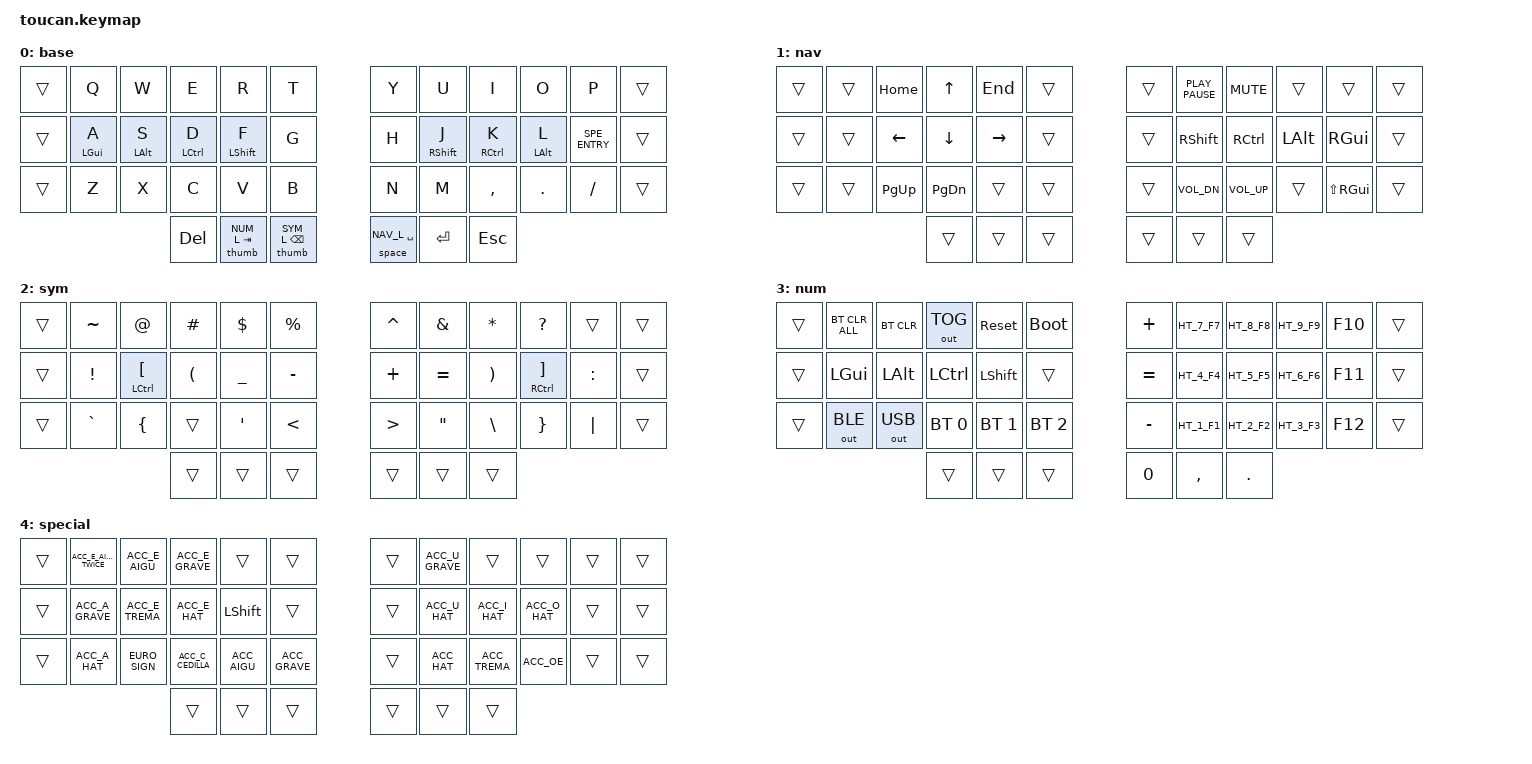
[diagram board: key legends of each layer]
/*
 * Copyright (c) 2021-2022 The ZMK Contributors
 *
 * SPDX-License-Identifier: MIT
 */

#include <behaviors.dtsi>
#include <input/processors.dtsi>
#include <dt-bindings/zmk/input_transform.h>
#include <dt-bindings/zmk/bt.h>
#include <dt-bindings/zmk/keys.h>
#include <dt-bindings/zmk/outputs.h>

#define BASE_L 0
#define NAV_L 1
#define SYM_L 2
#define NUM_L 3
#define SPE_L 4

// Keyboard keys positions
// 0  1  2  3  4  5               6  7  8  9  10 11
// 12 13 14 15 16 17             18 19 20 21 22 23
// 24 25 26 27 28 29             30 31 32 33 34 35
//             36 37 38        39 40 41
#define LEFT_HAND_KEYS                                      \
1  2  3  4  5                                               \
13 14 15 16 17                                              \
25 26 27 28 29

#define RIGHT_HAND_KEYS                                     \
                                    6  7  8  9  10          \
                                    18 19 20 21 22          \
                                    30 31 32 33 34

#define THUMB_KEYS                                          \
            36 37 38                39 40 41

&glidepoint_listener {
        input-processors = <&zip_xy_scaler 250 100>;
        precision_layer {
                layers = <2>;
                input-processors = <&zip_xy_scaler 110 100>;
        };
        scroller {
                layers = <3>;
                input-processors = <
                        &zip_xy_to_scroll_mapper
                        &zip_scroll_scaler 1 5
                        &zip_scroll_transform INPUT_TRANSFORM_X_INVERT
                >;
        };
};

/ {
        macros {
                #include "macros.dtsi"
        };

        combos {
                // Keyboard keys positions
                // 0  1  2  3  4  5               6  7  8  9  10 11
                // 12 13 14 15 16 17             18 19 20 21 22 23
                // 24 25 26 27 28 29             30 31 32 33 34 35
                //             36 37 38        39 40 41
                #define COMBO_KEYS_ESC 2 3 4 // "wer"

                #define COMBO_KEYS_SYM_CARET 1 13 // "qa"
                #define COMBO_KEYS_SYM_DOLLAR 5 17 // "tg"
                #define COMBO_KEYS_SYM_ASTERISK 6 18 // "yh"
                #define COMBO_KEYS_SYM_PLUS 26 14 // "xs"
                #define COMBO_KEYS_SYM_MINUS 33 21 // ".l"
                #define COMBO_KEYS_SYM_HASH 17 29 // "gb"
                #define COMBO_KEYS_SYM_GRAVE 13 25 // "az"

                #define COMBO_KEYS_ENTER 15 16 // "df"
                #define COMBO_KEYS_ENTER_CTRL 14 15 16 // "sdf"
                #define COMBO_KEYS_TAB 14 15 // "sd"

                #define COMBO_KEYS_CAPS 16 19 // "fj"
                #define COMBO_KEYS_APPS 25 34 // "z + /"

                #define COMBO_KEYS_VIM_SAVE 22 2 // "spe + w"
                #define COMBO_KEYS_VIM_SAVE_QUIT 22 1 // "spe + q"

                #define COMBO_KEYS_SYM_QUOTE 28 16 // "vf"
                #define COMBO_KEYS_SYM_DQUOTE 31 19 // "mj"
                #define COMBO_KEYS_SYM_LPAR 3 15 // "ed"
                #define COMBO_KEYS_SYM_RPAR 8 20 // "ik"
                #define COMBO_KEYS_SYM_LBKT 2 14 // "ws"
                #define COMBO_KEYS_SYM_RBKT 9 21 // "ol"
                #define COMBO_KEYS_SYM_EXCLAM 27 15 // "cd"
                #define COMBO_KEYS_SYM_QUESTION 32 20 // ",k"
                #define COMBO_KEYS_SYM_UNDER 4 16 // "rf"
                #define COMBO_KEYS_SYM_EQUAL 19 7 // "ju"
                #define COMBO_KEYS_SYM_AT 18 30 // "hn"
                #define COMBO_KEYS_SYM_COLON 10 22 // "p + spe"
                #define COMBO_KEYS_SYM_SEMI 22 34 // "spe/"

                #define COMBO_KEYS_CUT 25 26 // "zx"
                #define COMBO_KEYS_COPY 26 27 // "xc"
                #define COMBO_KEYS_PASTE 27 28 // "cv"
                #define COMBO_KEYS_SPACE 26 27 28 // "xcv"
                #define COMBO_KEYS_PLAIN_PASTE 28 29 // "vb"
                #include "combos.dtsi"
        };

        behaviors {
                #include "behaviors.dtsi"
                #include "home_rows.dtsi"
        };

        keymap {
                compatible = "zmk,keymap";

                base_layer {
                        display-name = "base";
                        bindings = <
&trans        &kp Q         &kp W         &kp E          &kp R           &kp T                       &kp Y  &kp U           &kp I          &kp O         &kp P         &trans
&trans        &hmrl LGUI A  &hmrl LALT S  &hmrl LCTRL D  &hmsl LSHIFT F  &kp G                       &kp H  &hmsr RSHIFT J  &hmrr RCTRL K  &hmrr LALT L  SPE_ENTRY    &trans
&trans        &kp Z         &kp X         &kp C          &kp V           &kp B                       &kp N  &kp M           &kp COMMA      &kp DOT       &kp SLASH     &trans
                                                            &kp DELETE  &thumb NUM_L TAB     &thumb SYM_L BACKSPACE    &space NAV_L SPACE  &kp ENTER  &kp ESC
                        >;
                };

                nav_layer {
                        display-name = "nav";
                        bindings = <
&trans  &trans          &kp HOME        &kp UP          &kp END           &trans                 &trans  &kp K_PLAY_PAUSE   &kp K_MUTE      &trans        &trans        &trans
&trans  &trans          &kp LEFT        &kp DOWN        &kp RIGHT         &trans                 &trans  &kp RSHIFT         &kp RCTRL       &kp LALT      &kp RGUI      &trans
&trans  &trans          &kp PAGE_UP     &kp PAGE_DOWN   &trans            &trans                 &trans  &kp K_VOL_DN       &kp K_VOL_UP    &trans        &kp LS(RGUI)  &trans
                                                            &trans  &trans  &trans            &trans  &trans  &trans
                        >;
                };

                sym_layer {
                        display-name = "sym";
                        bindings = <
&trans     &kp TILDE               &kp AT                  &kp HASH          &kp DOLLAR        &kp PERCENT        &kp CARET         &kp AMPS           &kp ASTRK                &kp QUESTION           &trans     &trans
&trans     &kp EXCL                &mt LCTRL LEFT_BRACKET  &kp LEFT_PARENTHESIS  &kp UNDERSCORE  &kp MINUS          &kp PLUS          &kp EQUAL          &kp RIGHT_PARENTHESIS    &mt RCTRL RIGHT_BRACKET  &kp COLON  &trans
&trans     &kp GRAVE               &kp LEFT_BRACE          &trans            &kp SINGLE_QUOTE  &kp LESS_THAN      &kp GREATER_THAN  &kp DOUBLE_QUOTES  &kp BACKSLASH            &kp RIGHT_BRACE        &kp PIPE    &trans
                                                            &trans  &trans  &trans            &trans  &trans  &trans
                        >;
                };

                num_layer {
                        display-name = "num";
                        bindings = <
&trans          &bt BT_CLR_ALL  &bt BT_CLR   &out OUT_TOG  &sys_reset   &bootloader       &kp PLUS   HT_7_F7  HT_8_F8  HT_9_F9  &kp F10       &trans
&trans          &kp LGUI        &kp LALT     &kp LCTRL     &kp LSHFT    &trans            &kp EQUAL  HT_4_F4  HT_5_F5  HT_6_F6  &kp F11       &trans
&trans          &out OUT_BLE    &out OUT_USB &bt BT_SEL 0  &bt BT_SEL 1 &bt BT_SEL 2      &kp MINUS  HT_1_F1  HT_2_F2  HT_3_F3  &kp F12       &trans
                                                            &trans  &trans  &trans         &kp NUMBER_0  &kp COMMA  &kp DOT
                        >;
                };

                special_layer {
                        display-name = "special";
                        bindings = <
&trans            ACC_E_AIGU_TWICE  ACC_E_AIGU  ACC_E_GRAVE      &trans            &trans   &trans  ACC_U_GRAVE  &trans      &trans      &trans      &trans
&trans            ACC_A_GRAVE       ACC_E_TREMA ACC_E_HAT        &kp LSHFT         &trans   &trans  ACC_U_HAT    ACC_I_HAT  ACC_O_HAT  &trans      &trans
&trans            ACC_A_HAT         EURO_SIGN   ACC_C_CEDILLA    ACC_AIGU          ACC_GRAVE  &trans  ACC_HAT      ACC_TREMA  ACC_OE     &trans      &trans
                                                            &trans  &trans  &trans         &trans  &trans  &trans
                        >;
                };

        };
};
